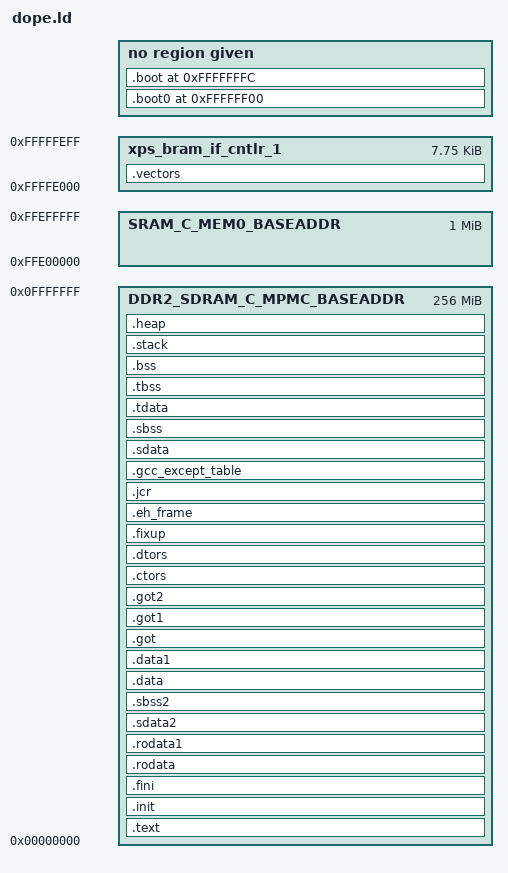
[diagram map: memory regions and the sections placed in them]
/*******************************************************************/
/*                                                                 */
/* This file is automatically generated by linker script generator.*/
/*                                                                 */
/* Version: Xilinx EDK 10.1.02 EDK_K_SP2.5                                */
/*                                                                 */
/* Copyright (c) 2004 Xilinx, Inc.  All rights reserved.           */
/*                                                                 */
/* Description : PowerPC440 Linker Script                          */
/*                                                                 */
/*******************************************************************/

_STACK_SIZE = DEFINED(_STACK_SIZE) ? _STACK_SIZE : 0x1000;
_HEAP_SIZE = DEFINED(_HEAP_SIZE) ? _HEAP_SIZE : 0x1000;

/* Define Memories in the system */

MEMORY
{
   DDR2_SDRAM_C_MPMC_BASEADDR : ORIGIN = 0x00000000, LENGTH = 0x10000000
   SRAM_C_MEM0_BASEADDR : ORIGIN = 0xFFE00000, LENGTH = 0x00100000
   xps_bram_if_cntlr_1 : ORIGIN = 0xFFFFE000, LENGTH = 0x00001F00
}

/* Specify the default entry point to the program */

ENTRY(_boot)
STARTUP(boot.o)

/* Define the sections, and where they are mapped in memory */

SECTIONS
{
.vectors : {
   __vectors_start = .;
   *(.vectors)
   __vectors_end = .;
} > xps_bram_if_cntlr_1

.text : {
   *(.text)
   *(.text.*)
   *(.gnu.linkonce.t.*)
} > DDR2_SDRAM_C_MPMC_BASEADDR

.init : {
   KEEP (*(.init))
} > DDR2_SDRAM_C_MPMC_BASEADDR

.fini : {
   KEEP (*(.fini))
} > DDR2_SDRAM_C_MPMC_BASEADDR

.rodata : {
   __rodata_start = .;
   *(.rodata)
   *(.rodata.*)
   *(.gnu.linkonce.r.*)
   __rodata_end = .;
} > DDR2_SDRAM_C_MPMC_BASEADDR

.rodata1 : {
   __rodata1_start = .;
   *(.rodata1)
   *(.rodata1.*)
   __rodata1_end = .;
} > DDR2_SDRAM_C_MPMC_BASEADDR

.sdata2 : {
   __sdata2_start = .;
   *(.sdata2)
   *(.sdata2.*)
   *(.gnu.linkonce.s2.*)
   __sdata2_end = .;
} > DDR2_SDRAM_C_MPMC_BASEADDR

.sbss2 : {
   __sbss2_start = .;
   *(.sbss2)
   *(.sbss2.*)
   *(.gnu.linkonce.sb2.*)
   __sbss2_end = .;
} > DDR2_SDRAM_C_MPMC_BASEADDR

.data : {
   __data_start = .;
   *(.data)
   *(.data.*)
   *(.gnu.linkonce.d.*)
   __data_end = .;
} > DDR2_SDRAM_C_MPMC_BASEADDR

.data1 : {
   __data1_start = .;
   *(.data1)
   *(.data1.*)
   __data1_end = .;
} > DDR2_SDRAM_C_MPMC_BASEADDR

.got : {
   *(.got)
} > DDR2_SDRAM_C_MPMC_BASEADDR

.got1 : {
   *(.got1)
} > DDR2_SDRAM_C_MPMC_BASEADDR

.got2 : {
   *(.got2)
} > DDR2_SDRAM_C_MPMC_BASEADDR

.ctors : {
   __CTOR_LIST__ = .;
   ___CTORS_LIST___ = .;
   KEEP (*crtbegin.o(.ctors))
   KEEP (*(EXCLUDE_FILE(*crtend.o) .ctors))
   KEEP (*(SORT(.ctors.*)))
   KEEP (*(.ctors))
   __CTOR_END__ = .;
   ___CTORS_END___ = .;
} > DDR2_SDRAM_C_MPMC_BASEADDR

.dtors : {
   __DTOR_LIST__ = .;
   ___DTORS_LIST___ = .;
   KEEP (*crtbegin.o(.dtors))
   KEEP (*(EXCLUDE_FILE(*crtend.o) .dtors))
   KEEP (*(SORT(.dtors.*)))
   KEEP (*(.dtors))
   __DTOR_END__ = .;
   ___DTORS_END___ = .;
} > DDR2_SDRAM_C_MPMC_BASEADDR

.fixup : {
   __fixup_start = .;
   *(.fixup)
   __fixup_end = .;
} > DDR2_SDRAM_C_MPMC_BASEADDR

.eh_frame : {
   *(.eh_frame)
} > DDR2_SDRAM_C_MPMC_BASEADDR

.jcr : {
   *(.jcr)
} > DDR2_SDRAM_C_MPMC_BASEADDR

.gcc_except_table : {
   *(.gcc_except_table)
} > DDR2_SDRAM_C_MPMC_BASEADDR

.sdata : {
   __sdata_start = .;
   *(.sdata)
   *(.sdata.*)
   *(.gnu.linkonce.s.*)
   __sdata_end = .;
} > DDR2_SDRAM_C_MPMC_BASEADDR

.sbss : {
   __sbss_start = .;
   *(.sbss)
   *(.sbss.*)
   *(.gnu.linkonce.sb.*)
   *(.scommon)
   __sbss_end = .;
} > DDR2_SDRAM_C_MPMC_BASEADDR

.tdata : {
   __tdata_start = .;
   *(.tdata)
   *(.tdata.*)
   *(.gnu.linkonce.td.*)
   __tdata_end = .;
} > DDR2_SDRAM_C_MPMC_BASEADDR

.tbss : {
   __tbss_start = .;
   *(.tbss)
   *(.tbss.*)
   *(.gnu.linkonce.tb.*)
   __tbss_end = .;
} > DDR2_SDRAM_C_MPMC_BASEADDR

.bss : {
   __bss_start = .;
   *(.bss)
   *(.bss.*)
   *(.gnu.linkonce.b.*)
   *(COMMON)
   . = ALIGN(4);
   __bss_end = .;
} > DDR2_SDRAM_C_MPMC_BASEADDR

.boot0 0xFFFFFF00 : {
   __boot0_start = .;
   *(.boot0)
   __boot0_end = .;
} 

.boot 0xFFFFFFFC : {
   __boot_start = .;
   *(.boot)
   __boot_end = .;
} 

/* Generate Stack and Heap Sections */

.stack : {
   _stack_end = .;
   . += _STACK_SIZE;
   . = ALIGN(16);
   __stack = .;
} > DDR2_SDRAM_C_MPMC_BASEADDR

.heap : {
   . = ALIGN(16);
   _heap_start = .;
   . += _HEAP_SIZE;
   . = ALIGN(16);
   _heap_end = .;
   _end = .;
} > DDR2_SDRAM_C_MPMC_BASEADDR

}

